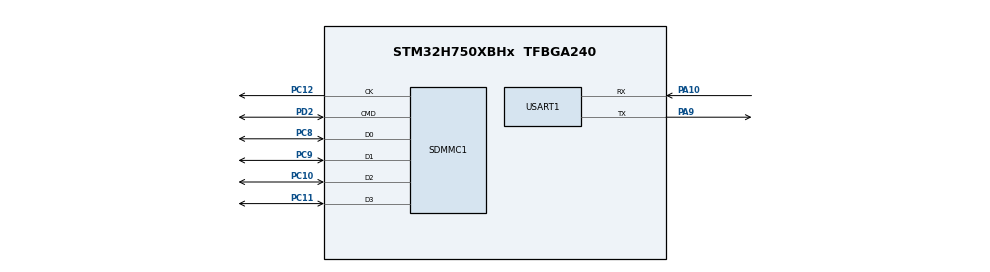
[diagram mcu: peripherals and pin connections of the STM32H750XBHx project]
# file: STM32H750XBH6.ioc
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Mcu.Family=STM32H7
Mcu.Name=STM32H750XBHx
Mcu.Package=TFBGA240
NVIC.PriorityGroup=NVIC_PRIORITYGROUP_4
NVIC.SDMMC1_IRQn=true\:14\:0\:true\:false\:true\:true\:true\:true
PA10.GPIO_Speed=GPIO_SPEED_FREQ_VERY_HIGH
PA10.Mode=Asynchronous
PA10.Signal=USART1_RX
PA9.GPIO_Speed=GPIO_SPEED_FREQ_VERY_HIGH
PA9.Mode=Asynchronous
PA9.Signal=USART1_TX
PC10.Mode=SD_4_bits_Wide_bus
PC10.Signal=SDMMC1_D2
PC11.Mode=SD_4_bits_Wide_bus
PC11.Signal=SDMMC1_D3
PC12.Mode=SD_4_bits_Wide_bus
PC12.Signal=SDMMC1_CK
PC8.Mode=SD_4_bits_Wide_bus
PC8.Signal=SDMMC1_D0
PC9.Mode=SD_4_bits_Wide_bus
PC9.Signal=SDMMC1_D1
PD2.Mode=SD_4_bits_Wide_bus
PD2.Signal=SDMMC1_CMD
PH0-OSC_IN\ (PH0).Mode=HSE-External-Oscillator
PH0-OSC_IN\ (PH0).Signal=RCC_OSC_IN
PH1-OSC_OUT\ (PH1).Mode=HSE-External-Oscillator
PH1-OSC_OUT\ (PH1).Signal=RCC_OSC_OUT
ProjectManager.HeapSize=0x200
ProjectManager.StackSize=0x400
ProjectManager.TargetToolchain=MDK-ARM V5.32
RCC.ADCFreq_Value=50390625
RCC.APB1Freq_Value=120000000
RCC.APB2Freq_Value=120000000
RCC.APB3Freq_Value=120000000
RCC.APB4Freq_Value=120000000
RCC.CortexFreq_Value=480000000
RCC.D1PPRE=RCC_APB3_DIV2
RCC.D2PPRE1=RCC_APB1_DIV2
RCC.D2PPRE2=RCC_APB2_DIV2
RCC.D3PPRE=RCC_APB4_DIV2
RCC.DIVM1=5
RCC.DIVN1=192
RCC.DIVQ1=4
RCC.HCLKFreq_Value=240000000
RCC.HPRE=RCC_HCLK_DIV2
RCC.PLLSourceVirtual=RCC_PLLSOURCE_HSE
RCC.SYSCLKFreq_VALUE=480000000
RCC.SYSCLKSource=RCC_SYSCLKSOURCE_PLLCLK
RCC.USBFreq_Value=240000000
SDMMC1.ClockDiv=6
USART1.VirtualMode-Asynchronous=VM_ASYNC
board=custom

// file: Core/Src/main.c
/* USER CODE BEGIN Header */
/**
  ******************************************************************************
  * @file           : main.c
  * @brief          : Main program body
  ******************************************************************************
  * @attention
  *
  * Copyright (c) 2024 STMicroelectronics.
  * All rights reserved.
  *
  * This software is licensed under terms that can be found in the LICENSE file
  * in the root directory of this software component.
  * If no LICENSE file comes with this software, it is provided AS-IS.
  *
  ******************************************************************************
  */
/* USER CODE END Header */
#include "main.h"

/* USER CODE BEGIN Includes */
#include "led.h"
#include "usart.h"
#include "sdmmc_sd.h"

/* USER CODE END Includes */

SD_HandleTypeDef hsd1;

UART_HandleTypeDef huart1;

void SystemClock_Config(void);
static void MX_GPIO_Init(void);
static void MX_USART1_UART_Init(void);
static void MX_SDMMC1_SD_Init(void);

int main(void)
{
  /* USER CODE BEGIN 1 */

	SCB_EnableICache();		// 使能ICache
	SCB_EnableDCache();		// 使能DCache

  /* USER CODE END 1 */

  /* MCU Configuration--------------------------------------------------------*/

  /* Reset of all peripherals, Initializes the Flash interface and the Systick. */
  HAL_Init();

  /* Configure the system clock */
  SystemClock_Config();

  /* Initialize all configured peripherals */
  MX_GPIO_Init();
  MX_USART1_UART_Init();
  MX_SDMMC1_SD_Init();
  /* USER CODE BEGIN 2 */
	LED_Init();					// 初始化LED引脚

	SDCard_Init();  // SD卡初始化

  /* USER CODE END 2 */

  /* Infinite loop */
  /* USER CODE BEGIN WHILE */
  printf ("\r\n 开始\r\n");

	SDCard_Test();	 	// SD卡读写测试

  while (1)
  {
    /* USER CODE END WHILE */

    /* USER CODE BEGIN 3 */
		LED1_Toggle;
		HAL_Delay(500);

  }
  /* USER CODE END 3 */
}

void SystemClock_Config(void)
{
  RCC_OscInitTypeDef RCC_OscInitStruct = {0};
  RCC_ClkInitTypeDef RCC_ClkInitStruct = {0};

  /** Supply configuration update enable
  */
  HAL_PWREx_ConfigSupply(PWR_LDO_SUPPLY);

  /** Configure the main internal regulator output voltage
  */
  __HAL_PWR_VOLTAGESCALING_CONFIG(PWR_REGULATOR_VOLTAGE_SCALE1);

  while(!__HAL_PWR_GET_FLAG(PWR_FLAG_VOSRDY)) {}

  __HAL_RCC_SYSCFG_CLK_ENABLE();
  __HAL_PWR_VOLTAGESCALING_CONFIG(PWR_REGULATOR_VOLTAGE_SCALE0);

  while(!__HAL_PWR_GET_FLAG(PWR_FLAG_VOSRDY)) {}

  /** Initializes the RCC Oscillators according to the specified parameters
  * in the RCC_OscInitTypeDef structure.
  */
  RCC_OscInitStruct.OscillatorType = RCC_OSCILLATORTYPE_HSE;
  RCC_OscInitStruct.HSEState = RCC_HSE_ON;
  RCC_OscInitStruct.PLL.PLLState = RCC_PLL_ON;
  RCC_OscInitStruct.PLL.PLLSource = RCC_PLLSOURCE_HSE;
  RCC_OscInitStruct.PLL.PLLM = 5;
  RCC_OscInitStruct.PLL.PLLN = 192;
  RCC_OscInitStruct.PLL.PLLP = 2;
  RCC_OscInitStruct.PLL.PLLQ = 4;
  RCC_OscInitStruct.PLL.PLLR = 2;
  RCC_OscInitStruct.PLL.PLLRGE = RCC_PLL1VCIRANGE_2;
  RCC_OscInitStruct.PLL.PLLVCOSEL = RCC_PLL1VCOWIDE;
  RCC_OscInitStruct.PLL.PLLFRACN = 0;
  if (HAL_RCC_OscConfig(&RCC_OscInitStruct) != HAL_OK)
  {
    Error_Handler();
  }

  /** Initializes the CPU, AHB and APB buses clocks
  */
  RCC_ClkInitStruct.ClockType = RCC_CLOCKTYPE_HCLK|RCC_CLOCKTYPE_SYSCLK
                              |RCC_CLOCKTYPE_PCLK1|RCC_CLOCKTYPE_PCLK2
                              |RCC_CLOCKTYPE_D3PCLK1|RCC_CLOCKTYPE_D1PCLK1;
  RCC_ClkInitStruct.SYSCLKSource = RCC_SYSCLKSOURCE_PLLCLK;
  RCC_ClkInitStruct.SYSCLKDivider = RCC_SYSCLK_DIV1;
  RCC_ClkInitStruct.AHBCLKDivider = RCC_HCLK_DIV2;
  RCC_ClkInitStruct.APB3CLKDivider = RCC_APB3_DIV2;
  RCC_ClkInitStruct.APB1CLKDivider = RCC_APB1_DIV2;
  RCC_ClkInitStruct.APB2CLKDivider = RCC_APB2_DIV2;
  RCC_ClkInitStruct.APB4CLKDivider = RCC_APB4_DIV2;

  if (HAL_RCC_ClockConfig(&RCC_ClkInitStruct, FLASH_LATENCY_4) != HAL_OK)
  {
    Error_Handler();
  }
}

static void MX_SDMMC1_SD_Init(void)
{

  hsd1.Instance = SDMMC1;
  hsd1.Init.ClockEdge = SDMMC_CLOCK_EDGE_RISING;
  hsd1.Init.ClockPowerSave = SDMMC_CLOCK_POWER_SAVE_DISABLE;
  hsd1.Init.BusWide = SDMMC_BUS_WIDE_4B;
  hsd1.Init.HardwareFlowControl = SDMMC_HARDWARE_FLOW_CONTROL_DISABLE;
  hsd1.Init.ClockDiv = 6;
  if (HAL_SD_Init(&hsd1) != HAL_OK)
  {
    Error_Handler();
  }

}

static void MX_USART1_UART_Init(void)
{

  huart1.Instance = USART1;
  huart1.Init.BaudRate = 115200;
  huart1.Init.WordLength = UART_WORDLENGTH_8B;
  huart1.Init.StopBits = UART_STOPBITS_1;
  huart1.Init.Parity = UART_PARITY_NONE;
  huart1.Init.Mode = UART_MODE_TX_RX;
  huart1.Init.HwFlowCtl = UART_HWCONTROL_NONE;
  huart1.Init.OverSampling = UART_OVERSAMPLING_16;
  huart1.Init.OneBitSampling = UART_ONE_BIT_SAMPLE_DISABLE;
  huart1.Init.ClockPrescaler = UART_PRESCALER_DIV1;
  huart1.AdvancedInit.AdvFeatureInit = UART_ADVFEATURE_NO_INIT;
  if (HAL_UART_Init(&huart1) != HAL_OK)
  {
    Error_Handler();
  }
  if (HAL_UARTEx_SetTxFifoThreshold(&huart1, UART_TXFIFO_THRESHOLD_1_8) != HAL_OK)
  {
    Error_Handler();
  }
  if (HAL_UARTEx_SetRxFifoThreshold(&huart1, UART_RXFIFO_THRESHOLD_1_8) != HAL_OK)
  {
    Error_Handler();
  }
  if (HAL_UARTEx_DisableFifoMode(&huart1) != HAL_OK)
  {
    Error_Handler();
  }

}

static void MX_GPIO_Init(void)
{

  /* GPIO Ports Clock Enable */
  __HAL_RCC_GPIOC_CLK_ENABLE();
  __HAL_RCC_GPIOD_CLK_ENABLE();
  __HAL_RCC_GPIOA_CLK_ENABLE();
  __HAL_RCC_GPIOH_CLK_ENABLE();

}

void Error_Handler(void)
{
  __disable_irq();
  while (1)
  {
  }
}
